# YTM32B1HA0 register map
Vendor: YTMicro; File version: 1.0
CPU: little endian, MPU, FPU, 2 interrupt priority bits
Registers are 32-bit, read-write, reset 0x0 unless marked. A register's access mark holds for its fields unless they carry their own. Offsets are from the block's base; [hi:lo] are bit positions; 'fields as' and 'values as' point back to an identical list.

## ENET (part 5 of 10) — Ethernet Quality-of-Service
Base 0x401E4000; register names take the prefix ENET_
0x714 TX_OCTET_COUNT_GOOD_BAD ro — This register provides the number of bytes transmitted by the DWC_ether_qos, exclusive of preamble and retried bytes, in good and bad packets.
  [31:0] TXOCTGB rw — This field indicates the number of bytes transmitted, exclusive of preamble and retried bytes, in good and bad packets.
0x718 TX_PACKET_COUNT_GOOD_BAD ro — This register provides the number of good and bad packets transmitted by DWC_ether_qos, exclusive of retried packets.
  [31:0] TXPKTGB rw — This field indicates the number of good and bad packets transmitted, exclusive of retried packets.
0x71C TX_BROADCAST_PACKETS_GOOD ro — This register provides the number of good broadcast packets transmitted by DWC_ether_qos.
  [15:0] TXBCASTG rw — This field indicates the number of good broadcast packets transmitted.
0x720 TX_MULTICAST_PACKETS_GOOD ro — This register provides the number of good multicast packets transmitted by DWC_ether_qos.
  [15:0] TXMCASTG rw — This field indicates the number of good multicast packets transmitted.
0x724 TX_64OCTETS_PACKETS_GOOD_BAD ro — This register provides the number of good and bad packets transmitted by DWC_ether_qos that are 64 bytes long, exclusive of preamble and retried bytes.
  [15:0] TX64OCTGB rw — This field indicates the number of good and bad packets transmitted with length 64 bytes, exclusive of preamble and retried packets.
0x728 TX_65TO127OCTETS_PACKETS_GOOD_BAD ro — This register provides the number of good and bad packets transmitted by DWC_ether_qos that are between 65 and 127 bytes long, exclusive of preamble and retried bytes.
  [15:0] TX65TO127OCTGB rw — This field indicates the number of good and bad packets transmitted with length between 65 and 127 bytes, exclusive of preamble and retried packets.
0x72C TX_128TO255OCTETS_PACKETS_GOOD_BAD ro — This register provides the number of good and bad packets transmitted by DWC_ether_qos that are between 128 and 255 bytes long, exclusive of preamble and retried bytes.
  [15:0] TX128TO255OCTGB rw — This field indicates the number of good and bad packets transmitted with length between 128 and 255 bytes, exclusive of preamble and retried packets.
0x730 TX_256TO511OCTETS_PACKETS_GOOD_BAD ro — This register provides the number of good and bad packets transmitted by DWC_ether_qos that are between 256 and 511 bytes long, exclusive of preamble and retried bytes.
  [15:0] TX256TO511OCTGB rw — This field indicates the number of good and bad packets transmitted with length between 256 and 511 bytes, exclusive of preamble and retried packets.
0x734 TX_512TO1023OCTETS_PACKETS_GOOD_BAD ro — This register provides the number of good and bad packets transmitted by DWC_ether_qos that are between 512 and 1023 bytes long, exclusive of preamble and retried bytes.
  [15:0] TX512TO1023OCTGB rw — This field indicates the number of good and bad packets transmitted with length between 512 and 1023 bytes, exclusive of preamble and retried packets.
0x738 TX_1024TOMAXOCTETS_PACKETS_GOOD_BAD ro — This register provides the number of good and bad packets transmitted by DWC_ether_qos that are between 1024 and 1518 bytes long, exclusive of preamble and retried bytes.
  [15:0] TX1024TOMAXOCTGB rw — This field indicates the number of good and bad packets transmitted with length between 1024 and 1518 bytes, exclusive of preamble and retried packets.
0x73C TX_UNICAST_PACKETS_GOOD_BAD ro — This register provides the number of good and bad unicast packets transmitted by DWC_ether_qos.
  [15:0] TXUCASTGB rw — This field indicates the number of good and bad unicast packets transmitted.
0x740 TX_MULTICAST_PACKETS_GOOD_BAD ro — This register provides the number of good and bad multicast packets transmitted by DWC_ether_qos.
  [15:0] TXMCASTGB rw — This field indicates the number of good and bad multicast packets transmitted.
0x744 TX_BROADCAST_PACKETS_GOOD_BAD ro — This register provides the number of good and bad broadcast packets transmitted by DWC_ether_qos.
  [15:0] TXBCASTGB rw — This field indicates the number of good and bad broadcast packets transmitted.
0x748 TX_UNDERFLOW_ERROR_PACKETS ro — This register provides the number of packets aborted by DWC_ether_qos because of packets underflow error.
  [15:0] TXUNDRFLW rw — This field indicates the number of packets transmitted that were aborted due to underflow.
0x74C TX_SINGLE_COLLISION_GOOD_PACKETS ro — This register provides the number of good packets transmitted by DWC_ether_qos after a single collision.
  [15:0] TXSNGLCOLG rw — This field indicates the number of good packets transmitted after a single collision.
0x750 TX_MULTIPLE_COLLISION_GOOD_PACKETS ro — This register provides the number of good packets transmitted by DWC_ether_qos after multiple collisions.
  [15:0] TXMULTCOLG rw — This field indicates the number of good packets transmitted after multiple collisions.
0x754 TX_DEFERRED_PACKETS ro — This register provides the number of packets transmitted by DWC_ether_qos after a deferral.
  [15:0] TXDEFRD rw — This field indicates the number of packets transmitted after a deferral.
0x758 TX_LATE_COLLISION_PACKETS ro — This register provides the number of packets transmitted by DWC_ether_qos after a late collision.
  [15:0] TXLATECOL rw — This field indicates the number of packets transmitted after a late collision.
0x75C TX_EXCESSIVE_COLLISION_PACKETS ro — This register provides the number of packets transmitted by DWC_ether_qos after excessive collisions.
  [15:0] TXEXSCOL rw — This field indicates the number of packets transmitted after excessive collisions.
0x760 TX_CARRIER_ERROR_PACKETS ro — This register provides the number of packets transmitted by DWC_ether_qos with a carrier error.
  [15:0] TXCARR rw — This field indicates the number of packets transmitted with a carrier error.
0x764 TX_OCTET_COUNT_GOOD ro — This register provides the number of bytes transmitted by DWC_ether_qos, exclusive of preamble, only in good packets.
  [15:0] TXOCTG rw — This field indicates the number of bytes transmitted, exclusive of preamble, only in good packets.
0x768 TX_PACKET_COUNT_GOOD ro — This register provides the number of packets transmitted by DWC_ether_qos, only in good packets.
  [15:0] TXPKTG rw — This field indicates the number of packets transmitted, only in good packets.
0x76C TX_EXCESSIVE_DEFERRAL_ERROR ro — This register provides the number of packets transmitted by DWC_ether_qos with excessive deferral.
  [15:0] TXEXSDEF rw — This field indicates the number of packets transmitted with excessive deferral.
0x770 TX_PAUSE_PACKETS ro — This register provides the number of pause packets transmitted by DWC_ether_qos.
  [15:0] TXPAUSE rw — This field indicates the number of pause packets transmitted.
0x774 TX_VLAN_PACKETS_GOOD ro — This register provides the number of VLAN packets transmitted by DWC_ether_qos, only in good packets.
  [15:0] TXVLANG rw — This field indicates the number of VLAN packets transmitted, only in good packets.
0x778 TX_OSIZE_PACKETS_GOOD ro — This register provides the number of packets transmitted by DWC_ether_qos with an oversized payload, only in good packets.
  [15:0] TXOSIZG rw — This field indicates the number of packets transmitted with an oversized payload, only in good packets.
0x780 RX_PACKETS_COUNT_GOOD_BAD ro — TThis register provides the number of good and bad packets received by DWC_ether_qos.
  [15:0] RXPKTGB rw — This field indicates the number of packets received, both good and bad.
0x784 RX_OCTET_COUNT_GOOD_BAD ro — This register provides the number of bytes received by DWC_ther_qos, exclusive of preamble, in good and bad packets.
  [15:0] RXOCTGB rw — This field indicates the number of bytes received, exclusive of preamble, both good and bad packets.
0x788 RX_OCTET_COUNT_GOOD ro — This register provides the number of bytes received by DWC_ether_qos, exclusive of preamble, only in good packets.
  [15:0] RXOCTG rw — This field indicates the number of bytes received, exclusive of preamble, only in good packets.
0x78C RX_BROADCAST_PACKETS_GOOD ro — This register provides the number of broadcast packets received by DWC_ether_qos, only in good packets.
  [15:0] RXBCASTG rw — This field indicates the number of broadcast packets received, only in good packets.
0x790 RX_MULTICAST_PACKETS_GOOD ro — This register provides the number of multicast packets received by DWC_ether_qos, only in good packets.
  [15:0] RXMCASTG rw — This field indicates the number of multicast packets received, only in good packets.
0x794 RX_CRC_ERROR_PACKETS ro — This register provides the number of packets received by DWC_ether_qos with a CRC error.
  [15:0] RXCRCERR rw — This field indicates the number of packets received with a CRC error.
0x798 RX_ALIGNMENT_ERROR_PACKETS ro — This register provides the number of packets received by DWC_ether_qos with alignment (dribble) error. It is valid only in 10/100 mode.
  [15:0] RXALGNERR rw — This field indicates the number of packets received with alignment (dribble) error. It is valid only in 10/100 mode.
0x79C RX_RUNT_ERROR_PACKETS ro — This register provides the number of packets received by DWC_ether_qos with runt (length less than 64 bytes and CRC error) error.
  [15:0] RXRUNTERR rw — This field indicates the number of packets received with runt (length less than 64 bytes and CRC error) error.
0x7A0 RX_JABBER_ERROR_PACKETS ro — This register provides the number of giant packets received by DWC_ether_qos with length (including CRC) greater than 1,518 bytes (1,522 bytes for VLAN tagged) and with CRC error. If Jumbo Packet mode is enabled, packets of length greater than 9,018 bytes (9,022 bytes for VLAN tagged) are considered as giant packets.
  [15:0] RXJABERR rw — This field indicates the number of giant packets received with length (including CRC) greater than 1,518 bytes (1,522 bytes for VLAN tagged) and with CRC error. If Jumbo Packet mode is enabled, packets of length greater than 9,018 bytes (9,022 bytes for VLAN tagged) are considered as giant packets.
0x7A4 RX_UNDERSIZE_PACKETS_GOOD ro — This register provides the number of packets received by DWC_ether_qos with length less than 64 bytes, without any errors.
  [15:0] RXUNDERSZG rw — This field indicates the number of packets received with length less than 64 bytes, without any errors.
0x7A8 RX_OVERSIZE_PACKETS_GOOD ro — This register provides the number of packets received by DWC_ether_qos without errors, with length greater than the maxsize (1,518 bytes or 1,522 bytes for VLAN tagged packets; 2000 bytes if enabled in the S2KP bit of the MAC_Configuration register).
  [15:0] RXOVERSZG rw — This field indicates the number of packets received without errors, with length greater than the maxsize (1,518 bytes or 1,522 bytes for VLAN tagged packets; 2000 bytes if enabled in the S2KP bit of the MAC_Configuration register).
0x7AC RX_64OCTETS_PACKETS_GOOD_BAD ro — This register provides the number of good and bad packets received by DWC_ether_qos with length 64 bytes, exclusive of the preamble.
  [15:0] RX64OCTGB rw — This field indicates the number of good and bad packets received with length 64 bytes, exclusive of the preamble.
0x7B0 RX_65TO127OCTETS_PACKETS_GOOD_BAD ro — This register provides the number of good and bad packets received by DWC_ether_qos with length between 65 and 127 bytes, exclusive of the preamble.
  [15:0] RX65TO127OCTGB rw — This field indicates the number of good and bad packets received with length between 65 and 127 bytes, exclusive of the preamble.
0x7B4 RX_128TO255OCTETS_PACKETS_GOOD_BAD ro — This register provides the number of good and bad packets received by DWC_ether_qos with length between 128 and 255 bytes, exclusive of the preamble.
  [15:0] RX128TO255OCTGB rw — This field indicates the number of good and bad packets received with length between 128 and 255 bytes, exclusive of the preamble.
0x7B8 RX_256TO511OCTETS_PACKETS_GOOD_BAD ro — This register provides the number of good and bad packets received by DWC_ether_qos with length between 256 and 511 bytes, exclusive of the preamble.
  [15:0] RX256TO511OCTGB rw — This field indicates the number of good and bad packets received with length between 256 and 511 bytes, exclusive of the preamble.
0x7BC RX_512TO1023OCTETS_PACKETS_GOOD_BAD ro — This register provides the number of good and bad packets received by DWC_ether_qos with length between 512 and 1,023 bytes, exclusive of the preamble.
  [15:0] RX512TO1023OCTGB rw — This field indicates the number of good and bad packets received with length between 512 and 1,023 bytes, exclusive of the preamble.
0x7C0 RX_1024TOMAXOCTETS_PACKETS_GOOD_BAD ro — This register provides the number of good and bad packets received by DWC_ether_qos with length between 1,024 and maxsize bytes, exclusive of the preamble.
  [15:0] RX1024TOMAXOCTGB rw — This field indicates the number of good and bad packets received with length between 1,024 and maxsize bytes, exclusive of the preamble.
0x7C4 RX_UNICAST_PACKETS_GOOD ro — This register provides the number of good unicast packets received by DWC_ether_qos.
  [15:0] RXUCASTG rw — This field indicates the number of good unicast packets received.
0x7C8 RX_LENGTH_ERROR_PACKETS ro — This register provides the number of packets received by DWC_ether_qos with length error (Length Type field not equal to packet size), for all packets with valid length field.
  [15:0] RXLENERR rw — This field indicates the number of packets received with length error (Length Type field not equal to packet size), for all packets with valid length field.
0x7CC RX_OUT_OF_RANGE_TYPE_PACKETS ro — This register provides the number of packets received by DWC_ether_qos with length field not equal to the valid packet size (greater than 1,500 but less than 1,536).
  [15:0] RXOUTOFRNG rw — This field indicates the number of packets received with length field not equal to the valid packet size (greater than 1,500 but less than 1,536).
0x7D0 RX_PAUSE_PACKETS ro — This register provides the number of good and valid Pause packets received by DWC_ether_qos.
  [15:0] RXPAUSEPKT rw — This field indicates the number of good and valid Pause packets received.
0x7D4 RX_FIFO_OVERFLOW_PACKETS ro — This register provides the number of packets received by DWC_ether_qos that were dropped due to the receive FIFO overflow.
  [15:0] RXFIFOOVFL rw — This field indicates the number of packets received that were dropped due to the receive FIFO overflow.
0x7D8 RX_VLAN_PACKETS_GOOD_BAD ro — This register provides the number of good and bad VLAN packets received by DWC_ether_qos.
  [15:0] RXVLANPKTGB rw — This field indicates the number of good and bad VLAN packets received.
0x7DC RX_WATCHDOG_ERROR_PACKETS ro — This register provides the number of packets received by DWC_ether_qos with error because of watchdog timeout error (packets with a data load larger than 2,048 bytes (when JE and WD bits are reset in MAC_Configuration register), 10,240 bytes (when JE bit is set and WD bit is reset in MAC_Configuration register), 16,384 bytes (when WD bit is set in MAC_Configuration register) or the value programmed in the MAC_Watchdog_Timeout register).
  [15:0] RXWDGERR rw — This field indicates the number of packets received with error because of watchdog timeout error (packets with a data load larger than 2,048 bytes (when JE and WD bits are reset in MAC_Configuration register), 10,240 bytes (when JE bit is set and WD bit is reset in MAC_Configuration register), 16,384 bytes (when WD bit is set in MAC_Configuration register) or the value programmed in the MAC_Watchdog_Timeout register).
0x7E0 RX_RECEIVE_ERROR_PACKETS ro — This register provides the number of packets received by DWC_ether_qos with Receive error or Packet Extension error on the GMII or MII interface.
  [15:0] RXRCVERR rw — TThis field indicates the number of packets received with Receive error or Packet Extension error on the GMII or MII interface.
0x7E4 RX_CONTROL_PACKETS_GOOD ro — This register provides the number of good control packets received by DWC_ether_qos.
  [15:0] RXCTRLG rw — This field indicates the number of good control packets received.
0x7EC TX_LPI_USEC_CNTR ro — This register provides the number of microseconds Tx LPI is asserted by DWC_ether_qos.
  [15:0] TXLPIUSC rw — This field indicates the number of microseconds Tx LPI is asserted. For every Tx LPI Entry and Exit, the Timer value can have an error of +/- 1 microsecond.
0x7F0 TX_LPI_TRAN_CNTR ro — This register provides the number of times DWC_ether_qos has entered Tx LPI.
  [15:0] TXLPITRC rw — This field indicates the number of times Tx LPI Entry has occurred. Even if Tx LPI Entry occurs in Automate Mode (because of LPITXA bit set in the LPI Control and Status register), the counter will increment.
0x7F4 RX_LPI_USEC_CNTR ro — This register provides the number of microseconds Rx LPI is sampled by DWC_ether_qos.
  [15:0] RXLPIUSC rw — This field indicates the number of microseconds Rx LPI is asserted. For every Rx LPI Entry and Exit, the Timer value can have an error of +/- 1 microsecond.
0x7F8 RX_LPI_TRAN_CNTR ro — This register provides the number of times DWC_ether_qos has sampled Rx LPI.
  [15:0] RXLPITRC rw — This field indicates the number of times Rx LPI Entry has occurred.
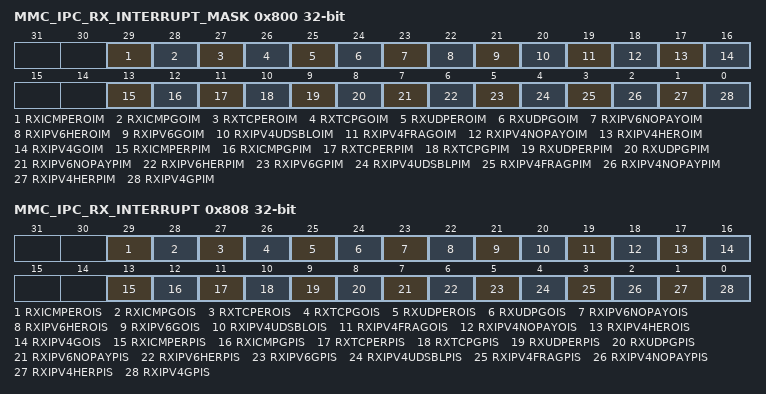
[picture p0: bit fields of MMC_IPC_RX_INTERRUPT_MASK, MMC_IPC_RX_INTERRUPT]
0x800 MMC_IPC_RX_INTERRUPT_MASK — This register maintains the mask for the interrupt generated from the receive IPC statistic counters. The MMC Receive Checksum Off load Interrupt Mask register maintains the masks for the interrupts generated when the receive IPC (Checksum Off load) statistic counters reach half their maximum value, and when they reach their maximum values. This register is 32 bits wide.
  [29] RXICMPEROIM — Setting this bit masks the interrupt when the rxicmp_err_octets counter reaches half of the maximum value or the maximum value.
    0=MMC Receive ICMP Error Octet Counter Interrupt Mask is disabled; 1=MMC Receive ICMP Error Octet Counter Interrupt Mask is enabled
  [28] RXICMPGOIM — Setting this bit masks the interrupt when the rxicmp_good_octets counter reaches half of the maximum value or the maximum value.
    0=MMC Receive ICMP Good Octet Counter Interrupt Mask is disabled; 1=MMC Receive ICMP Good Octet Counter Interrupt Mask is enabled
  [27] RXTCPEROIM — Setting this bit masks the interrupt when the rxtcp_err_octets counter reaches half of the maximum value or the maximum value.
    0=MMC Receive TCP Error Octet Counter Interrupt Mask is disabled; 1=MMC Receive TCP Error Octet Counter Interrupt Mask is enabled
  [26] RXTCPGOIM — Setting this bit masks the interrupt when the rxtcp_gd_octets counter reaches half of the maximum value or the maximum value.
    0=MMC Receive TCP Good Octet Counter Interrupt Mask is disabled; 1=MMC Receive TCP Good Octet Counter Interrupt Mask is enabled
  [25] RXUDPEROIM — Setting this bit masks the interrupt when the rxudp_err_octets counter reaches half of the maximum value or the maximum value.
    0=MMC Receive UDP Error Octet Counter Interrupt Mask is disabled; 1=MMC Receive UDP Error Octet Counter Interrupt Mask is enabled
  [24] RXUDPGOIM — Setting this bit masks the interrupt when the rxudp_gd_octets counter reaches half of the maximum value or the maximum value.
    0=MMC Receive IPV6 No Payload Octet Counter Interrupt Mask is disabled; 1=MMC Receive IPV6 No Payload Octet Counter Interrupt Mask is enabled
  [23] RXIPV6NOPAYOIM — Setting this bit masks the interrupt when the rxipv6_nopay_octets counter reaches half of the maximum value or the maximum value.
    0=MMC Receive IPV6 Header Error Octet Counter Interrupt Mask is disabled; 1=MMC Receive IPV6 Header Error Octet Counter Interrupt Mask is enabled
  [22] RXIPV6HEROIM — Setting this bit masks the interrupt when the rxipv6_hdrerr_octets counter reaches half of the maximum value or the maximum value.
    0=MMC Receive IPV6 Good Octet Counter Interrupt Mask is disabled; 1=MMC Receive IPV6 Good Octet Counter Interrupt Mask is enabled
  [21] RXIPV6GOIM — Setting this bit masks the interrupt when the rxipv6_gd_octets counter reaches half of the maximum value or the maximum value.
    values as RXIPV6HEROIM
  [20] RXIPV4UDSBLOIM — Setting this bit masks the interrupt when the rxipv4_udpbl_octets counter reaches half of the maximum value or the maximum value.
    0=MMC Receive IPV4 UDP Checksum Error Octet Counter Interrupt Mask is disabled; 1=MMC Receive IPV4 UDP Checksum Error Octet Counter Interrupt Mask is enabled
  [19] RXIPV4FRAGOIM — Setting this bit masks the interrupt when the rxipv4_frag_octets counter reaches half of the maximum value or the maximum value.
    0=MMC Receive IPV4 Fragmented Octet Counter Interrupt Mask is disabled; 1=MMC Receive IPV4 Fragmented Octet Counter Interrupt Mask is enabled
  [18] RXIPV4NOPAYOIM — Setting this bit masks the interrupt when the rxipv4_nopay_octets counter reaches half of the maximum value or the maximum value.
    0=MMC Receive IPV4 No Payload Octet Counter Interrupt Mask is disabled; 1=MMC Receive IPV4 No Payload Octet Counter Interrupt Mask is enabled
  [17] RXIPV4HEROIM — Setting this bit masks the interrupt when the rxipv4_hdrerr_octets counter reaches half of the maximum value or the maximum value.
    0=MMC Receive IPV4 Header Error Octet Counter Interrupt Mask is disabled; 1=MMC Receive IPV4 Header Error Octet Counter Interrupt Mask is enabled
  [16] RXIPV4GOIM — Setting this bit masks the interrupt when the rxipv4_gd_octets counter reaches half of the maximum value or the maximum value.
    0=MMC Receive IPV4 Good Octet Counter Interrupt Mask is disabled; 1=MMC Receive IPV4 Good Octet Counter Interrupt Mask is enabled
  [13] RXICMPERPIM — Setting this bit masks the interrupt when the rxicmp_err_pkts counter reaches half of the maximum value or the maximum value.
    0=MMC Receive ICMP Error Packet Counter Interrupt Mask is disabled; 1=MMC Receive ICMP Error Packet Counter Interrupt Mask is enabled
  [12] RXICMPGPIM — Setting this bit masks the interrupt when the rxicmp_gd_pkts counter reaches half of the maximum value or the maximum value.
    0=MMC Receive ICMP Good Packet Counter Interrupt Mask is disabled; 1=MMC Receive ICMP Good Packet Counter Interrupt Mask is enabled
  [11] RXTCPERPIM — Setting this bit masks the interrupt when the rxtcp_err_pkts counter reaches half of the maximum value or the maximum value.
    0=MMC Receive TCP Error Packet Counter Interrupt Mask is disabled; 1=MMC Receive TCP Error Packet Counter Interrupt Mask is enabled
  [10] RXTCPGPIM — Setting this bit masks the interrupt when the rxtcp_gd_pkts counter reaches half of the maximum value or the maximum value.
    0=MMC Receive TCP Good Packet Counter Interrupt Mask is disabled; 1=MMC Receive TCP Good Packet Counter Interrupt Mask is enabled
  [9] RXUDPERPIM — Setting this bit masks the interrupt when the rxudp_err_pkts counter reaches half of the maximum value or the maximum value.
    0=MMC Receive UDP Error Packet Counter Interrupt Mask is disabled; 1=MMC Receive UDP Error Packet Counter Interrupt Mask is enabled
  [8] RXUDPGPIM — Setting this bit masks the interrupt when the rxudp_gd_pkts counter reaches half of the maximum value or the maximum value.
    0=MMC Receive UDP Good Packet Counter Interrupt Mask is disabled; 1=MMC Receive UDP Good Packet Counter Interrupt Mask is enabled
  [7] RXIPV6NOPAYPIM — Setting this bit masks the interrupt when the rxipv6_nopay_pkts counter reaches half of the maximum value or the maximum value.
    0=MMC Receive IPV6 No Payload Packet Counter Interrupt Mask is disabled; 1=MMC Receive IPV6 No Payload Packet Counter Interrupt Mask is enabled
  [6] RXIPV6HERPIM — Setting this bit masks the interrupt when the rxipv6_hdrerr_pkts counter reaches half of the maximum value or the maximum value.
    0=MMC Receive IPV6 Header Error Packet Counter Interrupt Mask is disabled; 1=MMC Receive IPV6 Header Error Packet Counter Interrupt Mask is enabled
  [5] RXIPV6GPIM — Setting this bit masks the interrupt when the rxipv6_gd_pkts counter reaches half of the maximum value or the maximum value.
    0=MMC Receive IPV6 Good Packet Counter Interrupt Mask is disabled; 1=MMC Receive IPV6 Good Packet Counter Interrupt Mask is enabled
  [4] RXIPV4UDSBLPIM — Setting this bit masks the interrupt when the rxipv4_udsbl_pkts counter reaches half of the maximum value or the maximum value.
    0=MMC Receive IPV4 UDP Checksum Disabled Packet Counter Interrupt Mask is disabled; 1=MMC Receive IPV4 UDP Checksum Disabled Packet Counter Interrupt Mask is enabled
  [3] RXIPV4FRAGPIM — Setting this bit masks the interrupt when the rxipv4_frag_pkts counter reaches half of the maximum value or the maximum value.
    0=MMC Receive IPV4 Fragmented Packet Counter Interrupt Mask is disabled; 1=MMC Receive IPV4 Fragmented Packet Counter Interrupt Mask is enabled
  [2] RXIPV4NOPAYPIM — Setting this bit masks the interrupt when the rxipv4_nopay_pkts counter reaches half of the maximum value or the maximum value.
    0=MMC Receive IPV4 No Payload Packet Counter Interrupt Mask is disabled; 1=MMC Receive IPV4 No Payload Packet Counter Interrupt Mask is enabled
  [1] RXIPV4HERPIM — Setting this bit masks the interrupt when the rxipv4_hdrerr_pkts counter reaches half of the maximum value or the maximum value.
    0=MMC Receive IPV4 Header Error Packet Counter Interrupt Mask is disabled; 1=MMC Receive IPV4 Header Error Packet Counter Interrupt Mask is enabled
  [0] RXIPV4GPIM — Setting this bit masks the interrupt when the rxipv4_gd_pkts counter reaches half of the maximum value or the maximum value.
    0=MMC Receive IPV4 Good Packet Counter Interrupt Mask is disabled; 1=1
0x808 MMC_IPC_RX_INTERRUPT ro — This register maintains the interrupt that the receive IPC statistic counters generate. The MMC Receive Checksum Offload Interrupt register maintains the interrupts generated when receive IPC statistic counters reach half their maximum values (0x8000_0000 for 32 bit counter and 0x8000 for 16 bit counter), and when they cross their maximum values (0xFFFF_FFFF for 32 bit counter and 0xFFFF for 16 bit counter). When Counter Stop Rollover is set, the interrupts are set but the counter remains at all-ones. The MMC Receive Checksum Offload Interrupt register is 32 bit wide. When the MMC IPC counter that caused the interrupt is read, its corresponding interrupt bit is cleared. The counter's least-signifi- cant byte lane (Bits[7:0]) must be read to clear the interrupt bit.
  [29] RXICMPEROIS rw — This bit is set when the rxicmp_err_octets counter reaches half of the maximum value or the maximum value. Access restriction applies. Clears on read. Self-set to 1 on internal event.
    0=MMC Receive ICMP Error Octet Counter Interrupt Status not detected; 1=MMC Receive ICMP Error Octet Counter Interrupt Status detected
  [28] RXICMPGOIS rw — This bit is set when the rxicmp_gd_octets counter reaches half of the maximum value or the maximum value. Access restriction applies. Clears on read. Self-set to 1 on internal event.
    0=MMC Receive ICMP Good Octet Counter Interrupt Status not detected; 1=MMC Receive ICMP Good Octet Counter Interrupt Status detected
  [27] RXTCPEROIS rw — This bit is set when the rxtcp_err_octets counter reaches half of the maximum value or the maximum value. Access restriction applies. Clears on read. Self-set to 1 on internal event.
    0=MMC Receive TCP Error Octet Counter Interrupt Status not detected; 1=MMC Receive TCP Error Octet Counter Interrupt Status detected
  [26] RXTCPGOIS rw — This bit is set when the rxtcp_gd_octets counter reaches half of the maximum value or the maximum value. Access restriction applies. Clears on read. Self-set to 1 on internal event.
    0=MMC Receive TCP Good Octet Counter Interrupt Status not detected; 1=MMC Receive TCP Good Octet Counter Interrupt Status detected
  [25] RXUDPEROIS rw — This bit is set when the rxudp_err_octets counter reaches half of the maximum value or the maximum value. Access restriction applies. Clears on read. Self-set to 1 on internal event.
    0=MMC Receive UDP Error Octet Counter Interrupt Status not detected; 1=MMC Receive UDP Error Octet Counter Interrupt Status detected
  [24] RXUDPGOIS rw — This bit is set when the rxudp_gd_octets counter reaches half of the maximum value or the maximum value. Access restriction applies. Clears on read. Self-set to 1 on internal event.
    0=MMC Receive UDP Good Octet Counter Interrupt Status not detected; 1=MMC Receive UDP Good Octet Counter Interrupt Status detected
  [23] RXIPV6NOPAYOIS rw — This bit is set when the rxipv6_nopay_octets counter reaches half of the maximum value or the maximum value. Access restriction applies. Clears on read. Self-set to 1 on internal event.
    0=MMC Receive IPV6 No Payload Octet Counter Interrupt Status not detected; 1=MMC Receive IPV6 No Payload Octet Counter Interrupt Status detected
  [22] RXIPV6HEROIS rw — This bit is set when the rxipv6_hdrerr_octets counter reaches half of the maximum value or the maximum value. Access restriction applies. Clears on read. Self-set to 1 on internal event.
    0=MMC Receive IPV6 Header Error Octet Counter Interrupt Status not detected; 1=MMC Receive IPV6 Header Error Octet Counter Interrupt Status detected
  [21] RXIPV6GOIS rw — This bit is set when the rxipv6_gd_octets counter reaches half of the maximum value or the maximum value. Access restriction applies. Clears on read. Self-set to 1 on internal event.
    0=MMC Receive IPV6 Good Octet Counter Interrupt Status not detected; 1=MMC Receive IPV6 Good Octet Counter Interrupt Status detected
  [20] RXIPV4UDSBLOIS rw — This bit is set when the rxipv4_udsbl_octets counter reaches half of the maximum value or the maximum value. Access restriction applies. Clears on read. Self-set to 1 on internal event.
    0=MMC Receive IPV4 UDP Checksum Disabled Octet Counter Interrupt Status not detected; 1=MMC Receive IPV4 UDP Checksum Disabled Octet Counter Interrupt Status detected
  [19] RXIPV4FRAGOIS rw — This bit is set when the rxipv4_frag_octets counter reaches half of the maximum value or the maximum value. Access restriction applies. Clears on read. Self-set to 1 on internal event.
    0=MMC Receive IPV4 Fragmented Octet Counter Interrupt Status not detected; 1=MMC Receive IPV4 Fragmented Octet Counter Interrupt Status detected
  [18] RXIPV4NOPAYOIS rw — This bit is set when the rxipv4_nopay_octets counter reaches half of the maximum value or the maximum value. Access restriction applies. Clears on read. Self-set to 1 on internal event.
    0=MMC Receive IPV4 No Payload Octet Counter Interrupt Status not detected; 1=MMC Receive IPV4 No Payload Octet Counter Interrupt Status detected
  [17] RXIPV4HEROIS rw — This bit is set when the rxipv4_hdrerr_octets counter reaches half of the maximum value or the maximum value. Access restriction applies. Clears on read. Self-set to 1 on internal event.
    0=MMC Receive IPV4 Header Error Octet Counter Interrupt Status not detected; 1=MMC Receive IPV4 Header Error Octet Counter Interrupt Status detected
  [16] RXIPV4GOIS rw — This bit is set when the rxipv4_gd_octets counter reaches half of the maximum value or the maximum value. Access restriction applies. Clears on read. Self-set to 1 on internal event.
    0=MMC Receive IPV4 Good Octet Counter Interrupt Status not detected; 1=MMC Receive IPV4 Good Octet Counter Interrupt Status detected
  [13] RXICMPERPIS rw — This bit is set when the rxicmp_err_pkts counter reaches half of the maximum value or the maximum value. Access restriction applies. Clears on read. Self-set to 1 on internal event.
    0=MMC Receive ICMP Error Packet Counter Interrupt Status not detected; 1=MMC Receive ICMP Error Packet Counter Interrupt Status detected
  [12] RXICMPGPIS rw — This bit is set when the rxicmp_gd_pkts counter reaches half of the maximum value or the maximum value. Access restriction applies. Clears on read. Self-set to 1 on internal event.
    0=MMC Receive ICMP Good Packet Counter Interrupt Status not detected; 1=MMC Receive ICMP Good Packet Counter Interrupt Status detected
  [11] RXTCPERPIS rw — This bit is set when the rxtcp_err_pkts counter reaches half of the maximum value or the maximum value. Access restriction applies. Clears on read. Self-set to 1 on internal event.
    0=MMC Receive TCP Error Packet Counter Interrupt Status not detected; 1=MMC Receive TCP Error Packet Counter Interrupt Status detected
  [10] RXTCPGPIS rw — This bit is set when the rxtcp_gd_pkts counter reaches half of the maximum value or the maximum value. Access restriction applies. Clears on read. Self-set to 1 on internal event.
    0=MMC Receive TCP Good Packet Counter Interrupt Status not detected; 1=MMC Receive TCP Good Packet Counter Interrupt Status detected
  [9] RXUDPERPIS rw — This bit is set when the rxudp_err_pkts counter reaches half of the maximum value or the maximum value. Access restriction applies. Clears on read. Self-set to 1 on internal event.
    0=MMC Receive UDP Error Packet Counter Interrupt Status not detected; 1=MMC Receive UDP Error Packet Counter Interrupt Status detected
  [8] RXUDPGPIS rw — This bit is set when the rxudp_gd_pkts counter reaches half of the maximum value or the maximum value. Access restriction applies. Clears on read. Self-set to 1 on internal event.
    0=MMC Receive UDP Good Packet Counter Interrupt Status not detected; 1=MMC Receive UDP Good Packet Counter Interrupt Status detected
  [7] RXIPV6NOPAYPIS rw — This bit is set when the rxipv6_nopay_pkts counter reaches half of the maximum value or the maximum value. Access restriction applies. Clears on read. Self-set to 1 on internal event.
    0=MMC Receive IPV6 No Payload Packet Counter Interrupt Status not detected; 1=MMC Receive IPV6 No Payload Packet Counter Interrupt Status detected
  [6] RXIPV6HERPIS rw — This bit is set when the rxipv6_hdrerr_pkts counter reaches half of the maximum value or the maximum value. Access restriction applies. Clears on read. Self-set to 1 on internal event.
    0=MMC Receive IPV6 Header Error Packet Counter Interrupt Status not detected; 1=MMC Receive IPV6 Header Error Packet Counter Interrupt Status detected
  [5] RXIPV6GPIS rw — This bit is set when the rxipv6_gd_pkts counter reaches half of the maximum value or the maximum value. Access restriction applies. Clears on read. Self-set to 1 on internal event.
    0=MMC Receive IPV6 Good Packet Counter Interrupt Status not detected; 1=MMC Receive IPV6 Good Packet Counter Interrupt Status detected
  [4] RXIPV4UDSBLPIS rw — This bit is set when the rxipv4_udsbl_pkts counter reaches half of the maximum value or the maximum value. Access restriction applies. Clears on read. Self-set to 1 on internal event.
    0=MMC Receive IPV4 UDP Checksum Disabled Packet Counter Interrupt Status not detected; 1=MMC Receive IPV4 UDP Checksum Disabled Packet Counter Interrupt Status detected
  [3] RXIPV4FRAGPIS rw — This bit is set when the rxipv4_frag_pkts counter reaches half of the maximum value or the maximum value. Access restriction applies. Clears on read. Self-set to 1 on internal event. This bit is set when the rxipv4_frag_pkts counter reaches half of the maximum value or the maximum value.
    0=MMC Receive IPV4 Fragmented Packet Counter Interrupt Status not detected; 1=MMC Receive IPV4 Fragmented Packet Counter Interrupt Status detected
  [2] RXIPV4NOPAYPIS rw — This bit is set when the rxipv4_nopay_pkts counter reaches half of the maximum value or the maximum value. Access restriction applies. Clears on read. Self-set to 1 on internal event.
    0=MMC Receive IPV4 No Payload Packet Counter Interrupt Status not detected; 1=MMC Receive IPV4 No Payload Packet Counter Interrupt Status detected
  [1] RXIPV4HERPIS rw — This bit is set when the rxipv4_hdrerr_pkts counter reaches half of the maximum value or the maximum value. Access restriction applies. Clears on read. Self-set to 1 on internal event.
    0=MMC Receive IPV4 Header Error Packet Counter Interrupt Status not detected; 1=MMC Receive IPV4 Header Error Packet Counter Interrupt Status detected
  [0] RXIPV4GPIS rw — This bit is set when the rxipv4_gd_pkts counter reaches half of the maximum value or the maximum value. Access restriction applies. Clears on read. Self-set to 1 on internal event.
    0=MMC Receive IPV4 Good Packet Counter Interrupt Status not detected; 1=MMC Receive IPV4 Good Packet Counter Interrupt Status detected
0x810 RXIPV4_GOOD_PACKETS ro — This register provides the number of good IPv4 datagrams received by DWC_ether_qos with the TCP, UDP, or ICMP payload.
  [15:0] RXIPV4GDPKT rw — This field indicates the number of good IPv4 datagrams received with the TCP, UDP, or ICMP payload.
0x814 RXIPV4_HEADER_ERROR_PACKETS ro — This register provides the number of IPv4 datagrams received by DWC_ether_qos with header (checksum, length, or version mismatch) errors.
  [15:0] RXIPV4HDRERRPKT rw — This field indicates the number of IPv4 datagrams received with header (checksum, length, or version mismatch) errors.
0x818 RXIPV4_NO_PAYLOAD_PACKETS ro — This register provides the number of IPv4 datagram packets received by DWC_ether_qos that did not have a TCP, UDP, or ICMP payload.
  [15:0] RXIPV4NOPAYPKT rw — This field indicates the number of IPv4 datagram packets received that did not have a TCP, UDP, or ICMP payload.
0x81C RXIPV4_FRAGMENTED_PACKETS ro — This register provides the number of good IPv4 datagrams received by DWC_ether_qos with fragmentation.
  [15:0] RXIPV4FRAGPKT rw — This field indicates the number of good IPv4 datagrams received with fragmentation.
0x820 RXIPV4_UDP_CHECKSUM_DISABLED_PACKETS ro — This register provides the number of good IPv4 datagrams received by DWC_ether_qos with UDP checksum disabled.
  [15:0] RXIPV4UDSBLPKT rw — This field indicates the number of good IPv4 datagrams received that had a UDP payload with checksum disabled.
0x824 RXIPV6_GOOD_PACKETS ro — This register provides the number of good IPv6 datagrams received by DWC_ether_qos with the TCP, UDP, or ICMP payload.
  [15:0] RXIPV6GDPKT rw — This field indicates the number of good IPv6 datagrams received with the TCP, UDP, or ICMP payload.
0x828 RXIPV6_HEADER_ERROR_PACKETS ro — This register provides the number of IPv6 datagrams received by DWC_ether_qos with header (checksum, length, or version mismatch) errors.
  [15:0] RXIPV6HDRERRPKT rw — This field indicates the number of IPv6 datagrams received with header (checksum, length, or version mismatch) errors.
0x82C RXIPV6_NO_PAYLOAD_PACKETS ro — This register provides the number of IPv6 datagram packets received by DWC_ether_qos that did not have a TCP, UDP, or ICMP payload.
  [15:0] RXIPV6NOPAYPKT rw — This field indicates the number of IPv6 datagram packets received that did not have a TCP, UDP, or ICMP payload.
0x830 RXUDP_GOOD_PACKETS ro — This register provides the number of good UDP datagrams received by DWC_ether_qos.
  [15:0] RXUDPGDPKT rw — This field indicates the number of good IP datagrams received with a good UDP payload. This counter is not updated when the RxIPv4_UDP_Checksum_Disabled_Packets counter is incremented.
